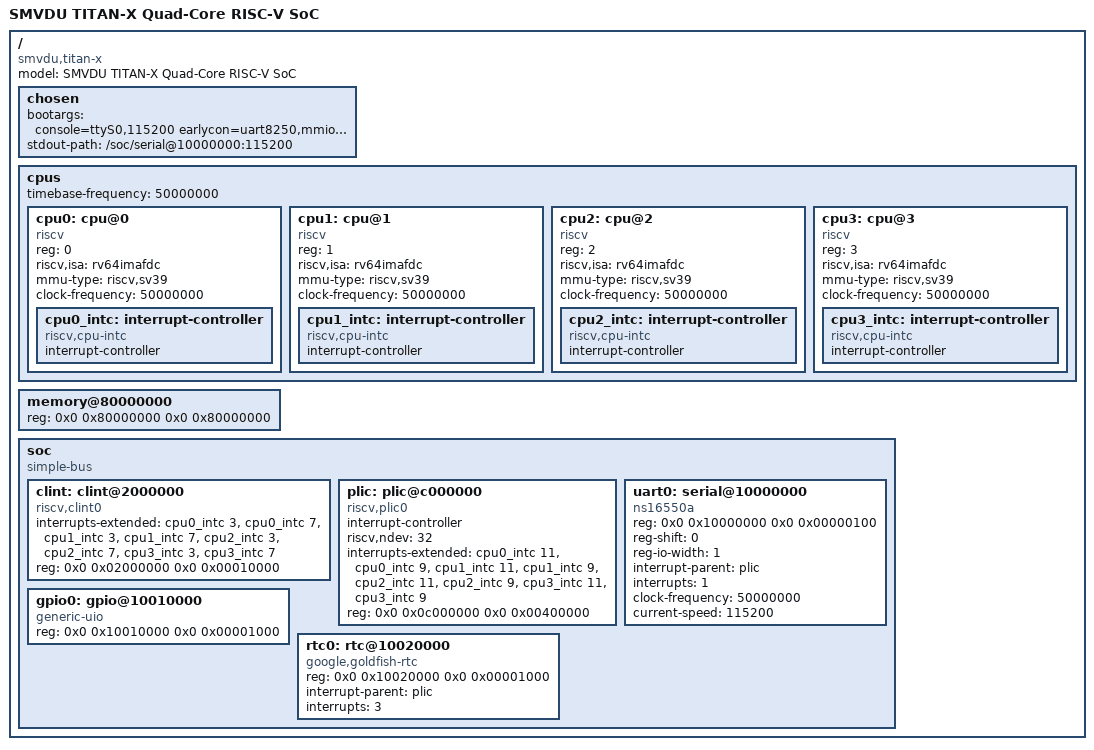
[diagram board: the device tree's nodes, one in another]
// SPDX-License-Identifier: Apache-2.0
// SMVDU TITAN-X SoC — Linux Device Tree Source (DTS)
// Target: 4x RV64GC Cores + AXI4 Bus + DDR4 RAM + UART16550 + CLINT + PLIC

/dts-v1/;

/ {
    #address-cells = <2>;
    #size-cells = <2>;
    compatible = "smvdu,titan-x", "riscv";
    model = "SMVDU TITAN-X Quad-Core RISC-V SoC";

    chosen {
        bootargs = "console=ttyS0,115200 earlycon=uart8250,mmio32,0x10000000 root=/dev/ram0 rdinit=/sbin/init rw loglevel=7";
        stdout-path = "/soc/serial@10000000:115200";
    };

    cpus {
        #address-cells = <1>;
        #size-cells = <0>;
        timebase-frequency = <50000000>; // 50 MHz CPU clock

        cpu0: cpu@0 {
            device_type = "cpu";
            reg = <0>;
            status = "okay";
            compatible = "riscv";
            riscv,isa = "rv64imafdc";
            mmu-type = "riscv,sv39";
            clock-frequency = <50000000>;

            cpu0_intc: interrupt-controller {
                #interrupt-cells = <1>;
                interrupt-controller;
                compatible = "riscv,cpu-intc";
            };
        };

        cpu1: cpu@1 {
            device_type = "cpu";
            reg = <1>;
            status = "okay";
            compatible = "riscv";
            riscv,isa = "rv64imafdc";
            mmu-type = "riscv,sv39";
            clock-frequency = <50000000>;

            cpu1_intc: interrupt-controller {
                #interrupt-cells = <1>;
                interrupt-controller;
                compatible = "riscv,cpu-intc";
            };
        };

        cpu2: cpu@2 {
            device_type = "cpu";
            reg = <2>;
            status = "okay";
            compatible = "riscv";
            riscv,isa = "rv64imafdc";
            mmu-type = "riscv,sv39";
            clock-frequency = <50000000>;

            cpu2_intc: interrupt-controller {
                #interrupt-cells = <1>;
                interrupt-controller;
                compatible = "riscv,cpu-intc";
            };
        };

        cpu3: cpu@3 {
            device_type = "cpu";
            reg = <3>;
            status = "okay";
            compatible = "riscv";
            riscv,isa = "rv64imafdc";
            mmu-type = "riscv,sv39";
            clock-frequency = <50000000>;

            cpu3_intc: interrupt-controller {
                #interrupt-cells = <1>;
                interrupt-controller;
                compatible = "riscv,cpu-intc";
            };
        };
    };

    memory@80000000 {
        device_type = "memory";
        reg = <0x0 0x80000000 0x0 0x80000000>; // 2048 MB DDR4 RAM
    };

    soc {
        #address-cells = <2>;
        #size-cells = <2>;
        compatible = "simple-bus";
        ranges;

        clint: clint@2000000 {
            compatible = "riscv,clint0";
            interrupts-extended = <
                &cpu0_intc 3 &cpu0_intc 7
                &cpu1_intc 3 &cpu1_intc 7
                &cpu2_intc 3 &cpu2_intc 7
                &cpu3_intc 3 &cpu3_intc 7
            >;
            reg = <0x0 0x02000000 0x0 0x00010000>;
        };

        plic: plic@c000000 {
            compatible = "riscv,plic0";
            #interrupt-cells = <1>;
            interrupt-controller;
            riscv,ndev = <32>;
            interrupts-extended = <
                &cpu0_intc 11 &cpu0_intc 9
                &cpu1_intc 11 &cpu1_intc 9
                &cpu2_intc 11 &cpu2_intc 9
                &cpu3_intc 11 &cpu3_intc 9
            >;
            reg = <0x0 0x0c000000 0x0 0x00400000>;
        };

        uart0: serial@10000000 {
            compatible = "ns16550a";
            reg = <0x0 0x10000000 0x0 0x00000100>;
            reg-shift = <0>;
            reg-io-width = <1>;
            interrupt-parent = <&plic>;
            interrupts = <1>;
            clock-frequency = <50000000>;
            current-speed = <115200>;
            status = "okay";
        };

        gpio0: gpio@10010000 {
            compatible = "generic-uio";
            reg = <0x0 0x10010000 0x0 0x00001000>;
            status = "okay";
        };

        rtc0: rtc@10020000 {
            compatible = "google,goldfish-rtc";
            reg = <0x0 0x10020000 0x0 0x00001000>;
            interrupt-parent = <&plic>;
            interrupts = <3>;
        };
    };
};
